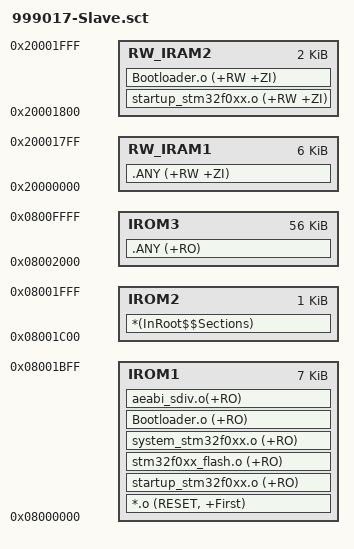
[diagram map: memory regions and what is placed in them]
; *************************************************************
; *** Scatter-Loading Description File generated by uVision ***
; *************************************************************

LR_IROM1 0x08000000 0x00001C00  {    ; load region size_region
  IROM1 0x08000000 0x00001C00  {  ; load address = execution address
   *.o (RESET, +First)
    startup_stm32f0xx.o (+RO)
    stm32f0xx_flash.o (+RO)
    system_stm32f0xx.o (+RO)
    Bootloader.o (+RO)
	aeabi_sdiv.o(+RO)
  }
  RW_IRAM1 0x20000000 0x00001800  {  ; RW data
   .ANY (+RW +ZI)
  }
  RW_IRAM2 0x20001800 0x00000800  {
    startup_stm32f0xx.o (+RW +ZI)
	Bootloader.o (+RW +ZI)
  }
}

LR_IROM2 0x08001C00 0x00000400  {
  IROM2 0x08001C00 0x00000400  {  ; load address = execution address
   *(InRoot$$Sections)
  }
}

LR_IROM3 0x08002000 0x0000E000  {
  IROM3 0x08002000 0x0000E000  {  ; load address = execution address
   .ANY (+RO)
  }
}
